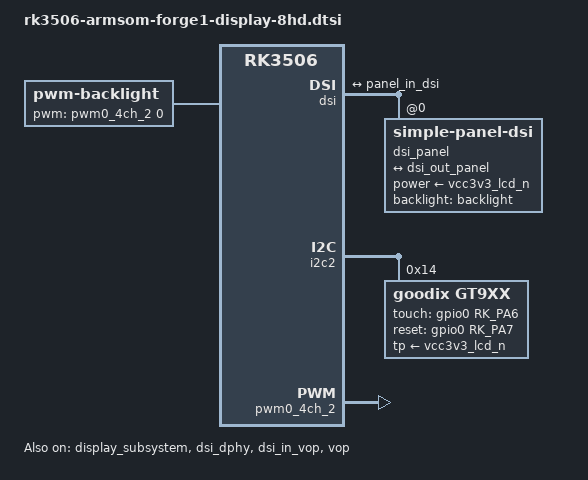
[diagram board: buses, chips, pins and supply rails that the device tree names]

/ {
	backlight: backlight {
		status = "okay";
		compatible = "pwm-backlight";
		pwms = <&pwm0_4ch_2 0 25000 0>;
		brightness-levels = <
			  0  20  20  21  21  22  22  23
			 23  24  24  25  25  26  26  27
			 27  28  28  29  29  30  30  31
			 31  32  32  33  33  34  34  35
			 35  36  36  37  37  38  38  39
			 40  41  42  43  44  45  46  47
			 48  49  50  51  52  53  54  55
			 56  57  58  59  60  61  62  63
			 64  65  66  67  68  69  70  71
			 72  73  74  75  76  77  78  79
			 80  81  82  83  84  85  86  87
			 88  89  90  91  92  93  94  95
			 96  97  98  99 100 101 102 103
			104 105 106 107 108 109 110 111
			112 113 114 115 116 117 118 119
			120 121 122 123 124 125 126 127
			128 129 130 131 132 133 134 135
			136 137 138 139 140 141 142 143
			144 145 146 147 148 149 150 151
			152 153 154 155 156 157 158 159
			160 161 162 163 164 165 166 167
			168 169 170 171 172 173 174 175
			176 177 178 179 180 181 182 183
			184 185 186 187 188 189 190 191
			192 193 194 195 196 197 198 199
			200 201 202 203 204 205 206 207
			208 209 210 211 212 213 214 215
			216 217 218 219 220 221 222 223
			224 225 226 227 228 229 230 231
			232 233 234 235 236 237 238 239
			240 241 242 243 244 245 246 247
			248 249 250 251 252 253 254 255
		>;
		default-brightness-level = <200>;
	};
};

&display_subsystem {
	logo-memory-region = <&drm_logo>;
	status = "okay";
};

&dsi {
	status = "okay";

	#address-cells = <1>;
	#size-cells = <0>;

	dsi_panel: panel@0 {
		status = "okay";
		compatible = "simple-panel-dsi";
		reg = <0>;
		backlight = <&backlight>;

		power-supply = <&vcc3v3_lcd_n>;
		width-mm = <107>;
		height-mm = <199>;
		dsi,flags = <(MIPI_DSI_MODE_VIDEO | MIPI_DSI_MODE_VIDEO_BURST |
			      MIPI_DSI_MODE_LPM | MIPI_DSI_MODE_NO_EOT_PACKET)>;
		dsi,format = <MIPI_DSI_FMT_RGB888>;
		dsi,lanes  = <2>;
		panel-init-sequence = [
			15 00 02 ee 50 
			39 00 03 ea 85 55 
			15 00 02 30 00 
			15 00 02 31 00 
			39 00 03 90 50 15 
			15 00 02 24 20 
			15 00 02 99 00 
			15 00 02 79 00 
			15 00 02 95 74 
			15 00 02 7a 20 
			15 00 02 97 09 
			15 00 02 7d 08 
			15 00 02 56 83  
			15 00 02 ee 60 
			15 00 02 30 01 
			15 00 02 27 22 
			15 00 02 3a a4  
			15 00 02 3b 00 
			15 00 02 3c 1a 
			15 00 02 3d 11 
			15 00 02 3e 93 
			15 00 02 42 64 
			15 00 02 43 64 
			15 00 02 44 0b 
			15 00 02 46 4e 
			15 00 02 8b 90 
			15 00 02 8d 45  
			15 00 02 91 11 
			15 00 02 92 11 
			15 00 02 93 9f 
			15 00 02 9a 00 
			15 00 02 9c 80 
			39 00 06 47 0f 24 2c 39 36 
			39 00 06 5A 0f 24 2c 39 36 
			39 00 06 4C 4a 40 51 31 2f 
			39 00 06 51 2d 10 25 1f 30 
			39 00 05 56 37 46 5b 7F 
			39 00 05 69 37 46 5b 7F 
			15 00 02 ee 70   
			39 00 05 00 03 07 00 01 
			39 00 05 04 08 0c 55 01 
			39 00 03 0c 05 3d 
			39 00 06 10 05 08 00 01 05  
			39 00 06 15 00 15 0d 08 00   
			39 00 03 29 05 3d 
			39 00 06 60 3c 3c 07 05 17   
			39 00 06 65 15 13 11 01 03   
			39 00 06 6a 3c 3c 3c 3c 3c   
			39 00 06 6f 3c 3c 3c 3c 3c 
			39 00 03 74 3C 3c 
			39 00 06 80 3c 3c 06 04 16   
			39 00 06 85 14 12 10 00 02   
			39 00 06 8a 3c 3c 3c 3c 3c 
			39 00 06 8f 3c 3c 3c 3c 3c 
			39 00 03 94 3c 3c 
			39 00 03 ea 00 00 
			15 00 02 ee 00
			05 c8 01 11
			05 c8 01 29 
		];

		panel-exit-sequence = [
			05 00 01 28
			05 00 01 10
		];

		disp_timings0: display-timings {
			native-mode = <&dsi0_timing0>;
			dsi0_timing0: timing0 {
				clock-frequency = <65000000>;
				hactive = <800>;
				vactive = <1280>;
				hsync-len = <20>;
				hback-porch = <20>;
				hfront-porch = <40>;
				vsync-len = <4>;
				vback-porch = <28>;
				vfront-porch = <30>;
				hsync-active = <0>;
				vsync-active = <0>;
				de-active = <0>;
				pixelclk-active = <0>;
			};
		};

		ports {
			#address-cells = <1>;
			#size-cells = <0>;

			port@0 {
				reg = <0>;
				panel_in_dsi: endpoint {
					remote-endpoint = <&dsi_out_panel>;
				};
			};
		};
	};

	ports {
		#address-cells = <1>;
		#size-cells = <0>;

		port@1 {
			reg = <1>;
			dsi_out_panel: endpoint {
				remote-endpoint = <&panel_in_dsi>;
			};
		};
	};
};

// &route_dsi {
//  status = "okay";
// };

&dsi_dphy {
	status = "okay";
};

&dsi_in_vop {
	status = "okay";
};

&i2c2 {
	pinctrl-names = "default";
	pinctrl-0 = <&rm_io4_i2c2_scl &rm_io5_i2c2_sda>;
	status = "okay";
	#address-cells = <1>;
	#size-cells = <0>;

	gt9xx: gt9xx@14 {
		status = "okay";
		compatible = "goodix,gt9xx";
		reg = <0x14>;
		pinctrl-names = "default";
		pinctrl-0 = <&gt9xx_gpio>;
		touch-gpio = <&gpio0 RK_PA6 IRQ_TYPE_LEVEL_HIGH>;
		reset-gpio = <&gpio0 RK_PA7 GPIO_ACTIVE_HIGH>;
		max-x = <800>;
		max-y = <1280>;
		tp-size = <911>;
		tp-supply = <&vcc3v3_lcd_n>; 
	};
};

&pinctrl {
	gt9xx {
		gt9xx_gpio: gt9xx-gpio {
			rockchip,pins =
				<0 RK_PA7 RK_FUNC_GPIO &pcfg_pull_none>,
				<0 RK_PA6 RK_FUNC_GPIO &pcfg_pull_up>;
		};
	};
};


&vop {
	status = "okay";
};

&pwm0_4ch_2 {
	pinctrl-names = "active";
	pinctrl-0 = <&rm_io29_pwm0_ch2>;
	status = "okay";
};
